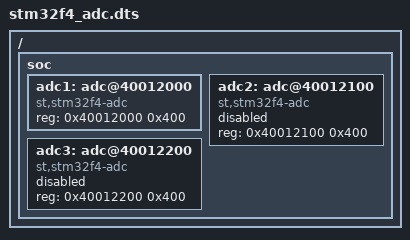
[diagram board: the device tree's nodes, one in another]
/dts-v1/;

/ {
    #address-cells = <1>;
    #size-cells = <1>;

    soc {
        #address-cells = <1>;
        #size-cells = <1>;

        adc1: adc@40012000 {
            compatible = "st,stm32f4-adc";
            reg = <0x40012000 0x400>;
            status = "okay";
        };

        adc2: adc@40012100 {
            compatible = "st,stm32f4-adc";
            reg = <0x40012100 0x400>;
            status = "disabled";
        };

        adc3: adc@40012200 {
            compatible = "st,stm32f4-adc";
            reg = <0x40012200 0x400>;
            status = "disabled";
        };
    };
};
